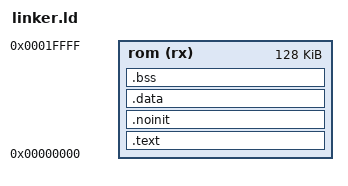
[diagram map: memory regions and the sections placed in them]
ENTRY(_start)

MEMORY {
	rom (rx) : ORIGIN = 0, LENGTH = 128k
}

SECTIONS {
	.text : {
		*(.startup)
		*(.text*)	/* Program code */
		. = ALIGN(4);
		*(.rodata*)	/* Read-only data */
		. = ALIGN(4);
	} >rom

	. = ALIGN(4);
	_etext = .;

	/* ram, but not cleared on reset, eg boot/app comms */
	.noinit (NOLOAD) : {
		*(.noinit*)
	} >rom
	. = ALIGN(4);

	.data : {
		_data = .;
		*(.data*)	/* Read-write initialized data */
		*(.ramtext*)	/* "text" functions to run in ram */
		. = ALIGN(4);
		_edata = .;
	} >rom

	.bss : {
		*(.bss*)	/* Read-write zero initialized data */
		*(COMMON)
		. = ALIGN(4);
		_ebss = .;
	} >rom

	/*
	 * The .eh_frame section appears to be used for C++ exception handling.
	 * You may need to fix this if you're using C++.
	 */
	/DISCARD/ : { *(.eh_frame) }

	. = ALIGN(4);
	end = .;
}
